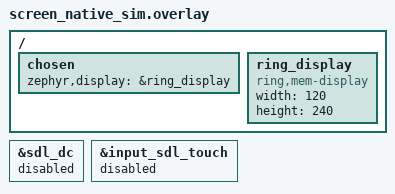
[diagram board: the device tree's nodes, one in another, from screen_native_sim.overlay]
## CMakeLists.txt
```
cmake_minimum_required(VERSION 3.20.0)

# RING_FACTORY_DIR and RING_RHW_DIR let a run point at a broken copy of ring_factory or ring_rhw to prove that these
# tests can fail (broken_run.sh). The other units are the finished ones, used as they are.
if(NOT DEFINED RING_RHW_DIR)
  set(RING_RHW_DIR ${CMAKE_CURRENT_SOURCE_DIR}/../../modules/ring_rhw)
endif()
if(NOT DEFINED RING_FACTORY_DIR)
  set(RING_FACTORY_DIR ${CMAKE_CURRENT_SOURCE_DIR}/../../modules/ring_factory)
endif()
set(RING_MODS ${CMAKE_CURRENT_SOURCE_DIR}/../../modules)
list(APPEND ZEPHYR_EXTRA_MODULES ${RING_RHW_DIR} ${RING_FACTORY_DIR} ${RING_MODS}/ring_core ${RING_MODS}/ring_store
     ${RING_MODS}/ring_audio ${RING_MODS}/ring_power ${RING_MODS}/ring_sys)

# the scenario ring_factory.screen (FACTORY_SCREEN=ON): the real screens part on the memory display, with the modules it needs
if(FACTORY_SCREEN)
  list(APPEND ZEPHYR_EXTRA_MODULES ${RING_MODS}/ring_screens ${RING_MODS}/ring_control ${RING_MODS}/ring_devices
       ${RING_MODS}/ring_inbox ${RING_MODS}/ring_time ${RING_MODS}/ring_iphone)
  list(APPEND EXTRA_CONF_FILE ${CMAKE_CURRENT_SOURCE_DIR}/screen.conf)
  if(BOARD MATCHES "native_sim")
    set(DTC_OVERLAY_FILE "${CMAKE_CURRENT_SOURCE_DIR}/app.overlay;${CMAKE_CURRENT_SOURCE_DIR}/screen_native_sim.overlay")
  else()
    set(DTC_OVERLAY_FILE "${CMAKE_CURRENT_SOURCE_DIR}/app.overlay;${CMAKE_CURRENT_SOURCE_DIR}/screen_bsim.overlay")
  endif()
endif()

find_package(Zephyr REQUIRED HINTS $ENV{ZEPHYR_BASE})
project(ring_factory_tests)

# rfa_logic.h is the unit's own (not public) header of the pure part: taken from the same copy as the code. rpw_priv.h is
# the power unit's test reset (tests of that unit use it the same way).
target_include_directories(app PRIVATE ${RING_FACTORY_DIR}/src ${RING_MODS}/ring_power/src ${CMAKE_CURRENT_SOURCE_DIR}/src)

target_sources(app PRIVATE
  src/common.c
  src/test_cmd.c
  src/test_mic.c
  src/test_input.c
  src/test_motor.c
  src/test_sign.c
  src/test_store.c
  src/test_radio.c
  src/test_charge.c
  src/test_xtal.c
  src/test_ship.c
  src/test_screen.c)
```

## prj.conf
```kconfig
CONFIG_ZTEST=y
CONFIG_RING_RHW=y
CONFIG_RING_RHW_SIM=y
CONFIG_RING_CORE=y
CONFIG_RING_STORE=y
CONFIG_RING_AUDIO=y
CONFIG_RING_POWER=y
CONFIG_RING_SYS=y
CONFIG_RING_FACTORY=y
CONFIG_THREAD_NAME=y
CONFIG_ZTEST_STACK_SIZE=8192
CONFIG_MAIN_STACK_SIZE=8192
# a test card: the T-STORE area and a few 2 s test recordings fit in 12,000 written sectors
CONFIG_RING_RHW_SIM_DISK_POOL=12000
CONFIG_RING_RHW_SIM_LOG_SIZE=16384
```

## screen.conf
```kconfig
# The scenario ring_factory.screen: the real screens part on the memory display (as tests/screens), so that T-SCREEN's frames
# can be read back from the panel's memory.
CONFIG_RING_SCREENS=y
CONFIG_RING_SCREENS_CAPTURE=y
CONFIG_HEAP_MEM_POOL_SIZE=4096
CONFIG_LVGL=y
CONFIG_LV_Z_AUTO_INIT=n
CONFIG_LV_COLOR_DEPTH_16=y
CONFIG_LV_FONT_MONTSERRAT_14=y
CONFIG_LV_FONT_MONTSERRAT_16=y
CONFIG_LV_FONT_MONTSERRAT_28=y
CONFIG_LV_FONT_MONTSERRAT_32=y
CONFIG_LV_Z_MEM_POOL_SIZE=32768
CONFIG_RING_SCREENS_STACK_SIZE=8192
CONFIG_THREAD_STACK_INFO=y
CONFIG_INIT_STACKS=y
CONFIG_THREAD_MONITOR=y
CONFIG_RING_SCREENS_SIGN_WAIT_MS=300
```

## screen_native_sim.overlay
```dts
/* The ring's panel stands in as a memory display; the SDL window display of native_sim is switched off. */
/ {
	chosen {
		zephyr,display = &ring_display;
	};
	ring_display: ring_display {
		compatible = "ring,mem-display";
		width = <120>;
		height = <240>;
	};
};

&sdl_dc {
	status = "disabled";
};

&input_sdl_touch {
	status = "disabled";
};
```

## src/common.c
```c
#include "common.h"

int fx_sign_answer;
uint32_t fx_sign_calls;
uint32_t fx_sign_at_log;
uint32_t fx_rec_calls;
uint8_t fx_rec_type = RREC_REC_TYPE_FACTORY;
uint32_t fx_frames_seen;
uint8_t fx_frame[FX_MAX_FRAMES];
int64_t fx_frame_ms[FX_MAX_FRAMES];
int64_t fx_frame_ticks[FX_MAX_FRAMES];
uint32_t fx_frames;
int fx_screen_rc;
uint64_t fx_xtal_grtc;
uint32_t fx_xtal_sof;
int fx_xtal_rc = -ENOTSUP;

static void (*tap_cb)(const int16_t *frames, uint32_t n);

/* ------------------------------------------------------------------ the recording path of the join, as a stand-in */
static void tap(const struct rst_chunk *c)
{
	const int16_t *p = (const int16_t *)(c->bytes + RREC_CHUNK_HEADER_BYTES);

	for (uint32_t off = 0; off < c->hdr.frames; off += RREC_BLOCK_FRAMES) {
		uint32_t n = c->hdr.frames - off;

		if (n > RREC_BLOCK_FRAMES) {
			n = RREC_BLOCK_FRAMES;
		}
		if (tap_cb != NULL) {
			tap_cb(p + 2u * off, n);
		}
		fx_frames_seen += n;
	}
}

static int fx_put(struct rst_chunk *c, rst_chunk_done_fn done)
{
	tap(c);
	return rst_put_chunk(c, done);
}

static void fx_log(uint16_t code, const uint8_t *args, size_t nargs)
{
	ARG_UNUSED(code);
	ARG_UNUSED(args);
	ARG_UNUSED(nargs);
}

int fx_test_recording(uint32_t ms, void (*on_block)(const int16_t *frames, uint32_t n), int64_t *mic_on_ms,
		      int64_t *mic_off_ms)
{
	struct rst_mount_info mi;
	struct rau_cut_result cut;
	bool mounted_here = false;
	uint32_t id = 0;
	int rc;

	fx_rec_calls++;
	tap_cb = on_block;
	if (!rst_mounted()) {
		rc = rst_mount(false, &mi);
		if (rc < 0) {
			return rc;
		}
		mounted_here = true;
	} else {
		memset(&mi, 0, sizeof(mi));
	}
	rc = rst_open(fx_rec_type, 0, &id);
	if (rc < 0) {
		return rc;
	}
	rc = rau_prepare(100);
	if (rc < 0) {
		return rc;
	}
	/* rec_mics_on() of the join: the sign first, VDD_MIC only on an answer of 0 */
	fx_sign_calls++;
	fx_sign_at_log = rhw_sim_log_count();
	if (fx_sign_answer != 0) {
		struct rst_close_args none;

		memset(&none, 0, sizeof(none));
		(void)rau_release();
		(void)rst_close(NULL, &none);
		if (mounted_here) {
			(void)rst_unmount();
		}
		return -ENODEV;
	}
	rc = rhw_pmic()->rail_set(RHW_RAIL_MIC, true, "rec_mics_on");
	if (rc < 0) {
		return rc;
	}
	*mic_on_ms = rhw_clock()->now_ms();
	k_sleep(K_MSEC(RREC_MIC_RAIL_WAIT_MS));
	struct rau_start_args a = {
		.recording_id = id, .recording_type = fx_rec_type, .boot_count = mi.boot_count, .time_set = false,
	};

	rc = rau_start(&a);
	if (rc < 0) {
		return rc;
	}
	int64_t t0 = rhw_clock()->now_ms();

	k_sleep(K_MSEC(ms));
	rc = rau_cut(t0 + ms, &cut);
	if (rc < 0) {
		return rc;
	}
	if (cut.last != NULL) {
		tap(cut.last);
	}
	rc = rst_close(cut.last, &cut.close);
	(void)rau_halt();
	(void)rhw_pmic()->rail_set(RHW_RAIL_MIC, false, "rec_mics_off");
	*mic_off_ms = rhw_clock()->now_ms();
	(void)rau_release();
	if (mounted_here) {
		(void)rst_unmount();
	}
	return rc < 0 ? rc : 0;
}

/* ------------------------------------------------------------------ the other stand-ins */
int fx_screen_frame(uint8_t which)
{
	if (fx_frames < FX_MAX_FRAMES) {
		fx_frame[fx_frames] = which;
		fx_frame_ms[fx_frames] = rhw_clock()->now_ms();
		fx_frame_ticks[fx_frames] = k_uptime_ticks();
	}
	fx_frames++;
	return fx_screen_rc;
}

static int fx_motor_on(uint32_t ms)
{
	/* the join's motor_on: MOTOR high for ms (ring_motor has patterns only; see factory-notes.md) */
	rhw_motor()->set(true);
	k_sleep(K_MSEC(ms));
	rhw_motor()->set(false);
	return 0;
}

static int fx_vbat(uint16_t *mv)
{
	struct rhw_pmic_sample s;
	int rc = rhw_pmic()->sample(&s);

	if (rc == 0) {
		*mv = s.mv;
	}
	return rc;
}

static int fx_charge(uint8_t *state, uint8_t *err, int32_t *ua)
{
	struct rhw_pmic_charge c;
	struct rhw_pmic_sample s;
	int rc = rhw_pmic()->charge_status(&c);

	if (rc == 0) {
		rc = rhw_pmic()->sample(&s);
	}
	if (rc == 0) {
		*state = c.state;
		*err = c.err_reason;
		*ua = s.ua;
	}
	return rc;
}

static int fx_xtal(uint64_t *grtc, uint32_t *sof)
{
	if (fx_xtal_rc != 0) {
		return fx_xtal_rc;
	}
	*grtc = fx_xtal_grtc;
	*sof = fx_xtal_sof;
	return 0;
}

struct rfa_ops fx_ops = {
	.test_recording = fx_test_recording,
	.screen_frame = fx_screen_frame,
	.motor_on = fx_motor_on,
	.vbat_mv = fx_vbat,
	.store_test = NULL, /* the built-in T-STORE of the factory part (ring_store) */
	.charge = fx_charge,
	.xtal_counts = fx_xtal,
	.flag = rsy_factory_flag,
	.flag_set = rsy_factory_flag_set,
};

/* ------------------------------------------------------------------ setup */
void fx_flag(bool on)
{
	struct rhw_persist p;

	memset(&p, 0, sizeof(p));
	p.factory_flag = on ? 1 : 0;
	rhw_sim_persist_set(&p);
	zassert_ok(rsy_init(fx_log), "rsy_init");
}

void fx_before(void *f)
{
	ARG_UNUSED(f);
	rpw_priv_reset();
	rhw_sim_reset();
	fx_sign_answer = 0;
	fx_sign_calls = 0;
	fx_sign_at_log = 0;
	fx_rec_calls = 0;
	fx_rec_type = RREC_REC_TYPE_FACTORY;
	fx_frames_seen = 0;
	fx_frames = 0;
	fx_screen_rc = 0;
	fx_xtal_rc = -ENOTSUP;
	tap_cb = NULL;
	zassert_ok(rst_init(NULL), "rst_init");
	struct rau_cb cb = { .put = fx_put };

	zassert_ok(rau_init(&cb), "rau_init");
	fx_flag(true);
	zassert_ok(rfa_init(&fx_ops), "rfa_init");
	rhw_sim_log_clear();
}

void fx_next_boot(void)
{
	rhw_sim_reboot();
	zassert_ok(rsy_init(fx_log), "rsy_init after reboot");
}

void fx_after(void *f)
{
	ARG_UNUSED(f);
	rfa_beacon_stop();
	k_sleep(K_MSEC(20));
}

enum rrec_status fx_do(const uint8_t *req, size_t n, bool in_factory_test, uint8_t *out, size_t *out_len,
		       enum rfa_effect *eff)
{
	return rfa_request(req, n, in_factory_test, out, out_len, eff);
}

enum rrec_status fx_do1(uint8_t sub, bool in_factory_test, uint8_t *out, size_t *out_len, enum rfa_effect *eff)
{
	return fx_do(&sub, 1, in_factory_test, out, out_len, eff);
}

/* ------------------------------------------------------------------ small helpers */
int32_t fx_find(uint16_t kind, uint32_t from)
{
	return rhw_sim_log_find(kind, from);
}

struct rhw_sim_ev fx_ev(uint32_t i)
{
	struct rhw_sim_ev e;

	zassert_true(rhw_sim_log_get(i, &e), "event %u exists", i);
	return e;
}

uint32_t fx_count(uint16_t kind)
{
	return rhw_sim_log_count_kind(kind);
}

uint32_t fx_mic_on_events(void)
{
	uint32_t n = 0;
	struct rhw_sim_ev e;

	for (uint32_t i = 0; i < rhw_sim_log_count(); i++) {
		if (rhw_sim_log_get(i, &e) && e.kind == RHW_EV_PMIC_RAIL && e.a0 == RHW_RAIL_MIC && e.a1 != 0) {
			n++;
		}
	}
	return n;
}

uint16_t fx_u16(const uint8_t *p)
{
	return (uint16_t)(p[0] | ((uint16_t)p[1] << 8));
}

uint32_t fx_u32(const uint8_t *p)
{
	return (uint32_t)fx_u16(p) | ((uint32_t)fx_u16(p + 2) << 16);
}

uint64_t fx_u64(const uint8_t *p)
{
	return (uint64_t)fx_u32(p) | ((uint64_t)fx_u32(p + 4) << 32);
}
```

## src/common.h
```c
/* Helpers of tests/factory (software step 6, unit U8): the stand-ins for the join and the ops table of the factory part.
 * "FW l.N" = line N of design/firmware.md. */
#ifndef FX_COMMON_H
#define FX_COMMON_H

#include <errno.h>
#include <string.h>

#include <zephyr/kernel.h>
#include <zephyr/ztest.h>

#include <ring_audio/rau.h>
#include <ring_factory/rfa.h>
#include <ring_power/rpw.h>
#include <ring_rhw/rhw.h>
#include <ring_rhw/rhw_sim.h>
#include <ring_rhw/rrec_spec.h>
#include <ring_store/rst.h>
#include <ring_sys/rsy.h>

#include "rfa_logic.h"
#include "rpw_priv.h"

extern struct rfa_ops fx_ops;

/* Reset everything the cases share: the simulated drivers, the finished units, the factory part with fx_ops, the factory
 * flag set (persistent settings, loaded by ring_sys). */
void fx_before(void *f);
void fx_after(void *f);
/* A reset of the ring (the three kept stores stay) and the settings loaded again. */
void fx_next_boot(void);
/* Set the persistent factory flag and load it again through ring_sys. */
void fx_flag(bool on);

/* One request. */
enum rrec_status fx_do(const uint8_t *req, size_t n, bool in_factory_test, uint8_t *out, size_t *out_len,
		       enum rfa_effect *eff);
enum rrec_status fx_do1(uint8_t sub, bool in_factory_test, uint8_t *out, size_t *out_len, enum rfa_effect *eff);

/* ---- the join's stand-ins (the join is not built yet) */
/* rec_mics_on() of the join: the sign, then VDD_MIC on, caller "rec_mics_on" (rrec.h). The answer of the sign is
 * fx_sign_answer (0 = drawn). */
extern int fx_sign_answer;
extern uint32_t fx_sign_calls;
extern uint32_t fx_sign_at_log;     /* rhw_sim_log_count() when the sign was last asked */
extern uint32_t fx_rec_calls;       /* test recordings asked for */
extern uint8_t fx_rec_type;         /* recording_type the stand-in opens with (default 2, a test recording) */
extern uint32_t fx_frames_seen;     /* frames the tap passed to on_block */
int fx_test_recording(uint32_t ms, void (*on_block)(const int16_t *frames, uint32_t n), int64_t *mic_on_ms,
		      int64_t *mic_off_ms);

/* T-SCREEN stand-in: the frames asked for, in order, with the uptime of each */
#define FX_MAX_FRAMES 16
extern uint8_t fx_frame[FX_MAX_FRAMES];
extern int64_t fx_frame_ms[FX_MAX_FRAMES];
extern int64_t fx_frame_ticks[FX_MAX_FRAMES];   /* k_uptime_ticks() of each frame (fix round 1, R6-13) */
extern uint32_t fx_frames;
extern int fx_screen_rc;
extern bool fx_real_screen;          /* test_screen.c: the real screens part draws */
int fx_screen_frame(uint8_t which);

/* T-XTAL stand-in */
extern uint64_t fx_xtal_grtc;
extern uint32_t fx_xtal_sof;
extern int fx_xtal_rc;

/* simulated-log helpers */
int32_t fx_find(uint16_t kind, uint32_t from);
struct rhw_sim_ev fx_ev(uint32_t i);
uint32_t fx_count(uint16_t kind);
/* entries of RHW_EV_PMIC_RAIL for the microphone rail that switch it on */
uint32_t fx_mic_on_events(void);

uint16_t fx_u16(const uint8_t *p);
uint32_t fx_u32(const uint8_t *p);
uint64_t fx_u64(const uint8_t *p);

#endif
```

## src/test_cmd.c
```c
/* Suite factory_cmd (software step 6, unit U8): the gate, the flag rules, the removed sub-command, the result layouts.
 * Rows C20, T11, T12, T23, X17 (the factory half). Expected values are typed from design/firmware.md 9.3 (l.1019 to
 * l.1037) and l.689 (status codes), never taken from the code under test. */
#include "common.h"

ZTEST_SUITE(factory_cmd, NULL, NULL, fx_before, fx_after, NULL);

/* the requests that need nothing but the sub-command byte, typed from l.1019 to l.1035, with the two that carry an
 * argument */
static const uint8_t plain[] = { 0x01, 0x02, 0x20, 0x40, 0x41, 0x50, 0x60, 0x70, 0x71, 0x7E, 0x7F };
static const uint8_t mic1[] = { 0x10, 0x01 };
static const uint8_t joy[] = { 0x30, 0xE8, 0x03 };   /* window 1,000 ms */
static const uint8_t centre[] = { 0x31, 0xE8, 0x03 };

#define NOT_ALLOWED 11  /* FW l.689 */
#define BAD_ARG 4       /* FW l.689 */

static uint32_t side_effects(void)
{
	return fx_count(RHW_EV_BEACON_START) + fx_count(RHW_EV_PERSIST_SAVE) + fx_count(RHW_EV_PMIC_RAIL) +
	       fx_count(RHW_EV_MOTOR) + fx_count(RHW_EV_MIC_START) + fx_rec_calls + fx_frames;
}

/* T11, C20: FACTORY ENTER only with the flag set; the flag is cleared only by SHIP_ENTER; SHIP_SAMPLE keeps it; with the
 * flag clear every FACTORY request answers NOT_ALLOWED (FW l.1019). */
ZTEST(factory_cmd, test_flag_rules)
{
	uint8_t out[RFA_OUT_MAX];
	size_t n;
	enum rfa_effect eff;
	struct rhw_persist p;

	/* flag clear: NOT_ALLOWED for every sub-command, in TRANSFER and in FACTORY_TEST, and nothing happens */
	fx_flag(false);
	for (int ft = 0; ft < 2; ft++) {
		for (size_t i = 0; i < sizeof(plain); i++) {
			n = 99;
			eff = RFA_EFFECT_ENTER;
			zassert_equal(fx_do(&plain[i], 1, ft != 0, out, &n, &eff), NOT_ALLOWED, "flag clear: sub 0x%02x ft %d",
				      plain[i], ft);
			zassert_equal(n, 0, "no response bytes");
			zassert_equal(eff, RFA_EFFECT_NONE, "no effect");
		}
		zassert_equal(fx_do(mic1, sizeof(mic1), ft != 0, out, &n, &eff), NOT_ALLOWED);
		zassert_equal(fx_do(joy, sizeof(joy), ft != 0, out, &n, &eff), NOT_ALLOWED);
		zassert_equal(fx_do(centre, sizeof(centre), ft != 0, out, &n, &eff), NOT_ALLOWED);
	}
	zassert_equal(side_effects(), 0, "a refused request does nothing: %u", side_effects());

	/* flag set: ENTER in TRANSFER is accepted and keeps the flag */
	fx_flag(true);
	zassert_equal(fx_do1(0x01, false, out, &n, &eff), 0);
	zassert_equal(eff, RFA_EFFECT_ENTER);
	zassert_equal(n, 1);
	zassert_equal(out[0], 0, "result pass");
	zassert_true(rsy_factory_flag(), "ENTER keeps the flag");

	/* EXIT: reboot effect, flag kept */
	zassert_equal(fx_do1(0x02, true, out, &n, &eff), 0);
	zassert_equal(eff, RFA_EFFECT_EXIT);
	zassert_true(rsy_factory_flag(), "EXIT keeps the flag");

	/* SHIP_SAMPLE (0x7E): ship mode, the flag stays 1, also after a reset: the ring can be tested again */
	zassert_equal(fx_do1(0x7E, true, out, &n, &eff), 0);
	zassert_equal(eff, RFA_EFFECT_SHIP_SAMPLE);
	zassert_equal(out[0], 0);
	rhw_sim_persist_get(&p);
	zassert_equal(p.factory_flag, 1, "SHIP_SAMPLE keeps the flag in the settings");
	zassert_equal(fx_count(RHW_EV_PERSIST_SAVE), 0, "SHIP_SAMPLE writes no setting");
	rfa_beacon_stop();
	fx_next_boot();
	zassert_true(rsy_factory_flag());
	zassert_equal(fx_do1(0x01, false, out, &n, &eff), 0, "after the wake FACTORY ENTER works again");
	zassert_equal(eff, RFA_EFFECT_ENTER);

	/* SHIP_ENTER (0x7F): the flag is cleared, and after a reset ENTER is refused */
	zassert_equal(fx_do1(0x7F, true, out, &n, &eff), 0);
	zassert_equal(eff, RFA_EFFECT_SHIP_ENTER);
	rhw_sim_persist_get(&p);
	zassert_equal(p.factory_flag, 0, "SHIP_ENTER clears the flag in the settings");
	zassert_false(rsy_factory_flag());
	rfa_beacon_stop();
	fx_next_boot();
	zassert_equal(fx_do1(0x01, false, out, &n, &eff), NOT_ALLOWED, "flag clear after SHIP_ENTER");
	zassert_equal(eff, RFA_EFFECT_NONE);

	/* the other sub-commands never clear it */
	fx_flag(true);
	zassert_equal(fx_do1(0x02, true, out, &n, &eff), 0);
	zassert_equal(fx_do1(0x70, true, out, &n, &eff), 0);
	zassert_true(rsy_factory_flag(), "no other sub-command clears the flag");

	/* outside FACTORY_TEST nothing but ENTER; in FACTORY_TEST ENTER is not answered again; the ship commands only in
	 * FACTORY_TEST (ruling R20: the beacon exists only there) */
	rhw_sim_log_clear();
	zassert_equal(fx_do1(0x20, false, out, &n, &eff), NOT_ALLOWED);
	zassert_equal(fx_do1(0x7F, false, out, &n, &eff), NOT_ALLOWED);
	zassert_equal(fx_do1(0x7E, false, out, &n, &eff), NOT_ALLOWED);
	zassert_equal(fx_do1(0x01, true, out, &n, &eff), NOT_ALLOWED);
	zassert_equal(fx_count(RHW_EV_BEACON_START), 0, "no beacon outside FACTORY_TEST");
	zassert_true(rsy_factory_flag(), "a refused SHIP_ENTER keeps the flag");
}

/* T23: sub-command 0x11 answers BAD_ARG (FW l.1037); so do unknown sub-commands and wrong argument lengths. */
ZTEST(factory_cmd, test_0x11_bad_arg)
{
	uint8_t out[RFA_OUT_MAX];
	size_t n = 99;
	enum rfa_effect eff = RFA_EFFECT_ENTER;
	const uint8_t x11[] = { 0x11 };
	const uint8_t x11a[] = { 0x11, 0x00 };
	const uint8_t x11b[] = { 0x11, 0x01, 0x02, 0x03 };

	zassert_equal(fx_do(x11, sizeof(x11), true, out, &n, &eff), BAD_ARG, "0x11 in FACTORY_TEST");
	zassert_equal(n, 0);
	zassert_equal(eff, RFA_EFFECT_NONE);
	zassert_equal(fx_do(x11a, sizeof(x11a), true, out, &n, &eff), BAD_ARG);
	zassert_equal(fx_do(x11b, sizeof(x11b), true, out, &n, &eff), BAD_ARG);
	zassert_equal(fx_do(x11, sizeof(x11), false, out, &n, &eff), BAD_ARG, "0x11 outside FACTORY_TEST");
	zassert_equal(side_effects(), 0, "the removed test runs nothing");
	/* unknown sub-commands and an empty request */
	for (unsigned s = 0; s < 256; s++) {
		bool known = false;

		for (size_t i = 0; i < sizeof(plain); i++) {
			known |= (plain[i] == s);
		}
		known |= (s == 0x10 || s == 0x30 || s == 0x31);
		if (known) {
			continue;
		}
		uint8_t r = (uint8_t)s;

		zassert_equal(fx_do(&r, 1, true, out, &n, &eff), BAD_ARG, "sub 0x%02x", s);
	}
	zassert_equal(fx_do(x11, 0, true, out, &n, &eff), BAD_ARG, "empty request");
	zassert_equal(side_effects(), 0);
}

/* wrong lengths and arguments (this unit's reading of the request layouts, rfa_logic.h) */
ZTEST(factory_cmd, test_bad_arguments)
{
	uint8_t out[RFA_OUT_MAX];
	size_t n;
	enum rfa_effect eff;
	const uint8_t m0[] = { 0x10, 0x00 };
	const uint8_t m3[] = { 0x10, 0x03 };
	const uint8_t m[] = { 0x10 };
	const uint8_t mx[] = { 0x10, 0x01, 0x01 };
	const uint8_t j0[] = { 0x30, 0x00, 0x00 };
	const uint8_t j10001[] = { 0x30, 0x11, 0x27 };
	const uint8_t j10000[] = { 0x30, 0x10, 0x27 };
	const uint8_t jshort[] = { 0x30, 0x10 };
	const uint8_t eextra[] = { 0x01, 0x00 };

	zassert_equal(fx_do(m0, sizeof(m0), true, out, &n, &eff), BAD_ARG);
	zassert_equal(fx_do(m3, sizeof(m3), true, out, &n, &eff), BAD_ARG);
	zassert_equal(fx_do(m, sizeof(m), true, out, &n, &eff), BAD_ARG);
	zassert_equal(fx_do(mx, sizeof(mx), true, out, &n, &eff), BAD_ARG);
	zassert_equal(fx_do(j0, sizeof(j0), true, out, &n, &eff), BAD_ARG, "window 0");
	zassert_equal(fx_do(j10001, sizeof(j10001), true, out, &n, &eff), BAD_ARG, "window above 10,000 ms");
	zassert_equal(fx_do(jshort, sizeof(jshort), true, out, &n, &eff), BAD_ARG);
	zassert_equal(fx_do(eextra, sizeof(eextra), false, out, &n, &eff), BAD_ARG);
	zassert_equal(side_effects(), 0);
	/* 10,000 ms is the largest window and is accepted (the test then runs its window) */
	zassert_equal(fx_do(j10000, sizeof(j10000), true, out, &n, &eff), 0);
	zassert_equal(out[0], 2, "no event in the window: timeout");
}

/* the pure layouts, typed byte for byte (little endian, FW l.70) */
ZTEST(factory_cmd, test_result_layout)
{
	uint8_t o[RFA_OUT_MAX];
	size_t n;

	/* result codes, FW l.1020 */
	zassert_equal(RREC_FAC_RESULT_PASS, 0);
	zassert_equal(RREC_FAC_RESULT_FAIL, 1);
	zassert_equal(RREC_FAC_RESULT_TIMEOUT, 2);

	/* T-MIC: result, rms L -230, rms R -233 (tenths of dBFS), runs 5 and 1,000 */
	n = rfa_put_mic(o, 0, -230, -233, 5, 1000);
	const uint8_t mic[] = { 0x00, 0x1A, 0xFF, 0x17, 0xFF, 0x05, 0, 0, 0, 0xE8, 0x03, 0, 0 };

	zassert_equal(n, sizeof(mic));
	zassert_mem_equal(o, mic, sizeof(mic));

	/* T-SIGN: result, four times 100, 1,100, 2,100, 3,100 ms */
	const int64_t t[4] = { 100, 1100, 2100, 3100 };
	const uint8_t sign[] = { 0x00, 0x64, 0, 0, 0, 0, 0, 0, 0, 0x4C, 0x04, 0, 0, 0, 0, 0, 0, 0x34, 0x08, 0, 0, 0, 0, 0, 0,
				 0x1C, 0x0C, 0, 0, 0, 0, 0, 0 };

	n = rfa_put_sign(o, 0, t);
	zassert_equal(n, sizeof(sign));
	zassert_mem_equal(o, sign, sizeof(sign));

	/* T-STORE: result, equal 1, write 1,000 us, read 2,000 us, deleted 3 */
	const uint8_t st[] = { 0x00, 0x01, 0xE8, 0x03, 0, 0, 0xD0, 0x07, 0, 0, 0x03, 0, 0, 0 };

	n = rfa_put_store(o, 0, true, 1000, 2000, 3);
	zassert_equal(n, sizeof(st));
	zassert_mem_equal(o, st, sizeof(st));

	/* T-JOY, T-CENTRE: result, dropped 0, count 2, (up at 100 ms), (long at 1,000 ms) */
	const struct rfa_evrec e[2] = { { RFA_IN_UP, 100 }, { RFA_IN_LONG, 1000 } };
	const uint8_t ev[] = { 0x00, 0x00, 0x02, 0x01, 0x64, 0, 0, 0, 0x09, 0xE8, 0x03, 0, 0 };

	n = rfa_put_events(o, 0, 0, e, 2);
	zassert_equal(n, sizeof(ev));
	zassert_mem_equal(o, ev, sizeof(ev));

	/* T-CHARGE through the request: state constant current (2), no error, 15,000 uA */
	struct rhw_pmic_sample s = { .mv = 3900, .ua = 15000, .temp_c_x10 = 250, .die_c_x10 = 300 };

	rhw_sim_pmic_script(&s, 1);
	rhw_sim_pmic_charge_state(2);
	enum rfa_effect eff;
	const uint8_t chg[] = { 0x00, 0x02, 0x00, 0x98, 0x3A, 0x00, 0x00 };

	zassert_equal(fx_do1(0x70, true, o, &n, &eff), 0);
	zassert_equal(n, sizeof(chg));
	zassert_mem_equal(o, chg, sizeof(chg));

	/* T-MOTOR through the request: VBAT 3,900 mV, 3,870 mV during the pulse, dip 30 mV */
	rhw_sim_pmic_motor_dip(30);
	const uint8_t mot[] = { 0x00, 0x3C, 0x0F, 0x1E, 0x0F, 0x1E, 0x00 };

	zassert_equal(fx_do1(0x40, true, o, &n, &eff), 0);
	zassert_equal(n, sizeof(mot));
	zassert_mem_equal(o, mot, sizeof(mot));

	/* T-XTAL through the request: 327,696 GRTC ticks against 10,000 frames: +488 (48.8 ppm) */
	fx_xtal_rc = 0;
	fx_xtal_grtc = 327696;
	fx_xtal_sof = 10000;
	const uint8_t xt[] = { 0x00, 0xE8, 0x01, 0, 0, 0x10, 0x00, 0x05, 0, 0, 0, 0, 0, 0x10, 0x27, 0, 0 };

	zassert_equal(fx_do1(0x71, true, o, &n, &eff), 0);
	zassert_equal(n, sizeof(xt));
	zassert_mem_equal(o, xt, sizeof(xt));

	/* the response is at most 256 bytes: the largest layout is T-JOY with RFA_MAX_EVENTS events */
	zassert_true(3u + 5u * RFA_MAX_EVENTS <= 256u);
}
```

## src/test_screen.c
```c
/* Suite factory_screen (software step 6, unit U8): T-SCREEN (0x20, FW l.1025): full red, green, blue, white, black, 1 s
 * each, then a grid. Rows T14. test_frame_sequence: the order and the 1 s spacing, on the ops stand-in. 
 * test_frames_reach_display (scenario ring_factory.screen only, FACTORY_SCREEN=ON): the real screens part
 * (rscr_factory_frame of decision D7, unit U9) on the memory display: the frame the display received is read back after
 * each frame and its pixels are counted. The camera is the jig's (not provable here). */
#include "common.h"

#if defined(CONFIG_RING_SCREENS)
#include <ring_core/rc_core.h>
#include <ring_screens/rmd.h>
#include <ring_screens/rscr.h>
#include <ring_screens/rscr_logic.h>

/* ---- the other modules behind struct rscr_ops, as empty stubs (the screens part asks for nothing in FACTORY_TEST) */
static struct rc_core core;
static int64_t skew;

static int64_t t_now(void)
{
	return k_uptime_get() + skew;
}

static uint8_t o_inbox_count(void)
{
	return 0;
}

static bool o_inbox_get(uint8_t i, struct rinbox_item *o)
{
	ARG_UNUSED(i);
	ARG_UNUSED(o);
	return false;
}

static void o_media_get(struct ripl_media *o)
{
	memset(o, 0, sizeof(*o));
}

static bool o_false(void)
{
	return false;
}

static uint8_t o_zero8(void)
{
	return 0;
}

static int o_uid(uint32_t uid)
{
	ARG_UNUSED(uid);
	return 0;
}

static int o_slot(uint8_t slot)
{
	ARG_UNUSED(slot);
	return 0;
}

static void o_void(void)
{
}

static void o_bool(bool on)
{
	ARG_UNUSED(on);
}

static void o_mode(enum rctl_mode m)
{
	ARG_UNUSED(m);
}

static int o_int(void)
{
	return 0;
}

static const struct rscr_ops sops = {
	.inbox_count = o_inbox_count, .inbox_get = o_inbox_get, .media_get = o_media_get, .ams_ready = o_false,
	.paired_mask = o_zero8, .active = o_zero8, .link_up = o_false, .dismiss = o_uid, .positive = o_uid,
	.mark_read = o_uid, .pair_open = o_slot, .pair_cancel = o_void, .dev_use = o_slot, .dev_remove = o_slot,
	.control_active = o_bool, .set_mode = o_mode, .power_off = o_int, .vibration = o_bool, .now_ms = t_now,
};

/* the glue's part: the screens' entry after every core step, and the lock fact before it */
static void after(struct rc_actions *a)
{
	enum rc_event last = a->last_row > 0 ? rscr_row_event(a->last_row) : RC_EV_COUNT;

	(void)rscr_glue_after(a, last, rc_core_state(&core), t_now());
}

static void core_event(enum rc_event ev)
{
	struct rc_actions a;

	rc_actions_clear(&a);
	core.facts.screen_on = rscr_lock_fact_now();
	rc_core_event(&core, ev, t_now(), &a);
	after(&a);
}

static void run_for(int ms)
{
	int64_t end = t_now() + ms;

	for (int64_t t = t_now() + 50; t <= end; t += 50) {
		struct rc_actions a;

		skew += 50;
		rc_actions_clear(&a);
		core.facts.screen_on = rscr_lock_fact_now();
		rc_core_tick(&core, t, &a);
		after(&a);
	}
}

static void *screen_setup(void)
{
	static bool started;

	if (!started) {
		rc_core_init(&core, RC_CENTRE_SW2, RC_ST_STANDBY, 0);
		zassert_equal(rscr_start(&sops), 0, "screens start (LVGL on the memory display)");
		started = true;
	}
	return NULL;
}

/* the frame the display received, and what the stand-in saw of each frame */
static uint8_t pic[RSCR_W * RSCR_H * 3];
static int white[6], black[6], red[6], green[6], blue[6];
static int frames_taken;
static bool first_row_white[6], first_col_white[6];

static int count_rgb(uint8_t r, uint8_t g, uint8_t b)
{
	int n = 0;

	for (int i = 0; i < RSCR_W * RSCR_H; i++) {
		n += pic[i * 3] == r && pic[i * 3 + 1] == g && pic[i * 3 + 2] == b;
	}
	return n;
}

/* the join's T-SCREEN call: rfa.h's number 0 to 5 is enum rscr_fac_frame minus one (FAC_RED to FAC_GRID); after the
 * call the screens thread has drawn and the display holds the frame */
static int real_frame(uint8_t which)
{
	int rc = rscr_factory_frame((enum rscr_fac_frame)(which + 1));

	if (rc != 0) {
		return rc;
	}
	rscr_sync();
	rscr_capture_rgb(pic);
	red[which] = count_rgb(255, 0, 0);
	green[which] = count_rgb(0, 255, 0);
	blue[which] = count_rgb(0, 0, 255);
	white[which] = count_rgb(255, 255, 255);
	black[which] = count_rgb(0, 0, 0);
	bool row = true, col = true;

	for (int x = 0; x < RSCR_W; x++) {
		row &= pic[x * 3] == 255 && pic[x * 3 + 1] == 255 && pic[x * 3 + 2] == 255;
	}
	for (int y = 0; y < RSCR_H; y++) {
		col &= pic[(y * RSCR_W) * 3] == 255 && pic[(y * RSCR_W) * 3 + 1] == 255;
	}
	first_row_white[which] = row;
	first_col_white[which] = col;
	fx_screen_frame(which); /* the time of each frame */
	frames_taken++;
	return 0;
}
#else
static void *screen_setup(void)
{
	return NULL;
}
#endif

ZTEST_SUITE(factory_screen, NULL, screen_setup, fx_before, fx_after, NULL);

ZTEST(factory_screen, test_frame_sequence)
{
	uint8_t out[RFA_OUT_MAX];
	size_t n = 0;
	enum rfa_effect eff;

	zassert_equal(fx_do1(0x20, true, out, &n, &eff), 0);
	zassert_equal(n, 1);
	zassert_equal(out[0], 0);
	/* red 0, green 1, blue 2, white 3, black 4, grid 5 (rfa.h), 1 s apart */
	for (uint32_t i = 0; i < fx_frames && i < FX_MAX_FRAMES; i++) {
		TC_PRINT("T-SCREEN stamps: frame %u at %lld ms, %lld ticks (%u ticks/s), spacing %lld ms\n", i, fx_frame_ms[i],
			 fx_frame_ticks[i], (unsigned)CONFIG_SYS_CLOCK_TICKS_PER_SEC, i > 0 ? fx_frame_ms[i] - fx_frame_ms[i - 1] : 0);
	}
	zassert_equal(fx_frames, 6);
	for (uint32_t i = 0; i < 6; i++) {
		zassert_equal(fx_frame[i], i, "frame %u", i);
		if (i > 0) {
			/* 1 s each (FW l.1025). Fix round 1 (review finding R6-13): the frames are spaced by k_sleep(1,000 ms) in
			 * rfa.c (run_screen), not by a periodic timer: each wait is at least 1,000 ms and ends on the next kernel
			 * tick (the kernel adds one tick to a relative timeout), so a frame comes 1,000 ms plus up to one tick
			 * after the one before. Measured in ticks (not in whole ms, whose floor made the result depend on the
			 * moment the earlier cases ended): at least 1,000,000 us and less than 1,000 ms + 1 ms (the tolerance:
			 * one tick is 100 us at 10,000 ticks per second) */
			int64_t us = k_ticks_to_us_floor64((uint64_t)(fx_frame_ticks[i] - fx_frame_ticks[i - 1]));

			zassert_true(us >= 1000000 && us < 1001000, "1 s each (FW l.1025): frame %u came %lld us after the one "
				     "before", i, us);
		}
	}
	/* a refused frame ends the test with a fail */
	fx_frames = 0;
	fx_screen_rc = -EIO;
	zassert_equal(fx_do1(0x20, true, out, &n, &eff), 0);
	zassert_equal(out[0], 1);
	zassert_equal(fx_frames, 1, "the first refusal ends the test");
}

#if defined(CONFIG_RING_SCREENS)
/* T14: T-SCREEN on the real screens part: every one of the 240 x 120 = 28,800 pixels is the colour (FW l.1025: full red,
 * green, blue, white, black), then a grid with lit lines on black whose first row and first column are lit (no dead edge). */
ZTEST(factory_screen, test_frames_reach_display)
{
	uint8_t out[RFA_OUT_MAX];
	size_t n = 0;
	enum rfa_effect eff;
	struct rmd_stats m;

	/* the real core, from STANDBY into FACTORY_TEST: VBUS in, USB configured, the flag, the factory ENTER */
	core_event(RC_EV_VBUS_IN);
	run_for(200);
	core_event(RC_EV_USB_CONFIGURED);
	run_for(200);
	zassert_equal(rc_core_state(&core), RC_ST_TRANSFER);
	core.facts.factory_flag = true;
	core_event(RC_EV_FACTORY_ENTER);
	run_for(200);
	zassert_equal(rc_core_state(&core), RC_ST_FACTORY_TEST, "FACTORY_TEST");
	rscr_sync();

	fx_ops.screen_frame = real_frame;
	zassert_ok(rfa_init(&fx_ops));
	frames_taken = 0;
	fx_frames = 0;
	zassert_equal(fx_do1(0x20, true, out, &n, &eff), 0);
	fx_ops.screen_frame = fx_screen_frame;
	zassert_ok(rfa_init(&fx_ops));
	zassert_equal(out[0], 0, "pass");
	zassert_equal(frames_taken, 6, "six frames reached the display");
	zassert_equal(red[0], RSCR_W * RSCR_H, "red: every pixel (255, 0, 0), found %d", red[0]);
	zassert_equal(green[1], RSCR_W * RSCR_H, "green: every pixel (0, 255, 0), found %d", green[1]);
	zassert_equal(blue[2], RSCR_W * RSCR_H, "blue: every pixel (0, 0, 255), found %d", blue[2]);
	zassert_equal(white[3], RSCR_W * RSCR_H, "white: every pixel (255, 255, 255), found %d", white[3]);
	zassert_equal(black[4], RSCR_W * RSCR_H, "black: every pixel (0, 0, 0), found %d", black[4]);
	/* the grid: lit and dark pixels, edges lit */
	zassert_true(white[5] > 1000 && black[5] > 1000, "grid: %d white, %d black pixels", white[5], black[5]);
	zassert_true(first_row_white[5] && first_col_white[5], "the grid's first row and first column are lit");
	zassert_equal(red[5] + green[5] + blue[5], 0, "no colour in the grid");
	for (int i = 1; i < 6; i++) {
		/* 1 s each (FW l.1025), plus the time the screens thread takes to draw and the read-back */
		zassert_true(fx_frame_ms[i] - fx_frame_ms[i - 1] >= 1000 && fx_frame_ms[i] - fx_frame_ms[i - 1] <= 1200,
			     "frame %d came %lld ms after the one before", i, fx_frame_ms[i] - fx_frame_ms[i - 1]);
	}
	rmd_stats_get(&m);
	zassert_false(m.blanked, "the panel is on");
	core_event(RC_EV_FACTORY_EXIT);
	run_for(100);
}
#endif
```

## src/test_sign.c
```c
/* Suite factory_sign (software step 6, unit U8): T-SIGN (0x41, FW l.1029): two 1 s test recordings 1 s apart; the ring
 * reports the times VDD_MIC went on and off. Rows T17. The camera is the jig's (not provable here). */
#include "common.h"

ZTEST_SUITE(factory_sign, NULL, NULL, fx_before, fx_after, NULL);

ZTEST(factory_sign, test_two_recordings_times)
{
	uint8_t out[RFA_OUT_MAX];
	size_t n = 0;
	enum rfa_effect eff;
	int64_t on_log[2], off_log[2];
	int no = 0, nf = 0;
	struct rhw_sim_ev e;

	rhw_sim_mic_source(RHW_SIM_MIC_SINE, -20);
	zassert_equal(fx_do1(0x41, true, out, &n, &eff), 0);
	zassert_equal(n, 33, "T-SIGN answers 33 bytes");
	zassert_equal(out[0], 0, "pass");
	zassert_equal(fx_rec_calls, 2, "two test recordings");
	zassert_equal(fx_sign_calls, 2, "the sign was asked for each");
	int64_t t[4];

	for (int i = 0; i < 4; i++) {
		t[i] = (int64_t)fx_u64(&out[1 + 8 * i]);
	}
	/* the times of VDD_MIC on and off in the one event log of the simulated drivers */
	for (uint32_t i = 0; i < rhw_sim_log_count(); i++) {
		zassert_true(rhw_sim_log_get(i, &e));
		if (e.kind == RHW_EV_PMIC_RAIL && e.a0 == RHW_RAIL_MIC) {
			if (e.a1 != 0 && no < 2) {
				on_log[no++] = e.t_us / 1000;
			} else if (e.a1 == 0 && nf < 2) {
				off_log[nf++] = e.t_us / 1000;
			}
		}
	}
	zassert_equal(no, 2, "VDD_MIC on twice");
	zassert_equal(nf, 2, "VDD_MIC off twice");
	zassert_within(t[0], on_log[0], 1, "first on");
	zassert_within(t[1], off_log[0], 1, "first off");
	zassert_within(t[2], on_log[1], 1, "second on");
	zassert_within(t[3], off_log[1], 1, "second off");
	zassert_true(t[0] < t[1] && t[1] < t[2] && t[2] < t[3], "on, off, on, off in order");
	/* each recording lasts 1 s (the stop waits for the block holding the mark and for the input to drain), the second
	 * starts 1 s after the first ended (FW l.1029) */
	zassert_true(t[1] - t[0] >= 1000 && t[1] - t[0] <= 1250, "first recording %lld ms", t[1] - t[0]);
	zassert_true(t[3] - t[2] >= 1000 && t[3] - t[2] <= 1250, "second recording %lld ms", t[3] - t[2]);
	zassert_true(t[2] - t[1] >= 1000 && t[2] - t[1] <= 1100, "the gap between them %lld ms", t[2] - t[1]);

	/* both are test recordings (type 2) on the card */
	struct rst_rec_info list[4];
	uint16_t count = 0;

	zassert_ok(rst_mount(false, &(struct rst_mount_info){ 0 }));
	zassert_ok(rst_list(0, 4, list, &count));
	zassert_equal(count, 2);
	zassert_equal(list[0].type, 2);
	zassert_equal(list[1].type, 2);
	zassert_ok(rst_unmount());
}
```
